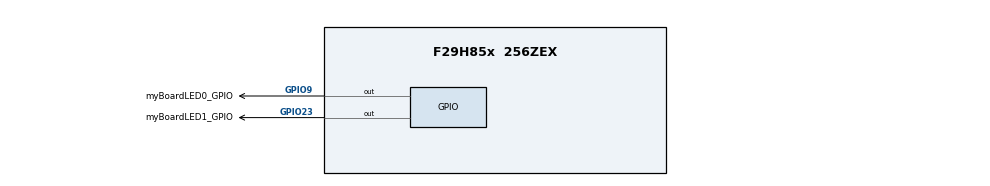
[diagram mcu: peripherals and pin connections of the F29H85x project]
/**
 * @cliArgs --device "F29H85x" --package "256ZEX" --part "F29H85x_256ZEX" --context "CPU1" --product "MCU_SDK_F29H85x@1.02.02.00"
 * @versions {"tool":"1.25.0+4237"}
 */

    
const divider15       = system.clockTree["PLL_REFDIV"];
divider15.divideValue = 1;

const multiplier1         = system.clockTree["PLL_IMULT"];
multiplier1.multiplyValue = 40;

const mux7       = system.clockTree["OSCCLKSRCSEL"];
mux7.inputSelect = "INTOSC2";

/**
 * Import the modules used in this configuration.
 */
const cputimer  = scripting.addModule("/driverlib/cputimer.js", {}, false);
const cputimer1 = cputimer.addInstance();
const gpio      = scripting.addModule("/driverlib/gpio.js", {}, false);
const gpio1     = gpio.addInstance();
const gpio2     = gpio.addInstance();
const interrupt = scripting.addModule("/driverlib/interrupt.js");
const jtag      = scripting.addModule("/driverlib/jtag.js");

/**
 * Write custom configuration values to the imported modules.
 */
cputimer1.$name              = "myCPUTIMER0";
cputimer1.startTimer         = true;
cputimer1.enableInterrupt    = true;
cputimer1.registerInterrupts = true;
cputimer1.timerPeriod        = 200000000;
cputimer1.periphClock.$name  = "driverlib_perClock0";

gpio1.$name             = "myBoardLED0_GPIO";
gpio1.direction         = "GPIO_DIR_MODE_OUT";
gpio1.writeInitialValue = true;
gpio1.gpioPin.$assign   = "GPIO9";

gpio2.$name             = "myBoardLED1_GPIO";
gpio2.direction         = "GPIO_DIR_MODE_OUT";
gpio2.writeInitialValue = true;
gpio2.initialValue      = 1;
gpio2.gpioPin.$assign   = "GPIO23";
